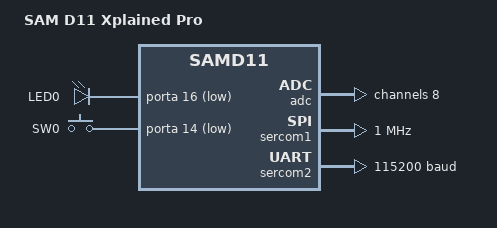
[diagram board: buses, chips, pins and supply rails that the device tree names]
/*
 * Copyright (c) 2018 Sean Nyekjaer
 *
 * SPDX-License-Identifier: Apache-2.0
 */

 /dts-v1/;
 #include <freq.h>
 #include <atmel/samd1x.dtsi>
 #include <atmel/samd11.dtsi>
 //#include <atmel/samx2xx18.dtsi>
 #include "samd11_xpro-pinctrl.dtsi"
 #include <zephyr/dt-bindings/input/input-event-codes.h>
 
 / {
	 model = "SAM D11 Xplained Pro";
	 compatible = "samd11,xpro", "atmel,samd11d14am", "atmel,samd11";
 
	 chosen {
		 zephyr,console = &sercom2;
		 zephyr,shell-uart = &sercom2;
		 zephyr,sram = &sram0;
		 zephyr,flash = &flash0;
	 };
 
	 /* These aliases are provided for compatibility with samples */
	 aliases {
		 led0 = &led0;
		 sw0 = &user_button;
		 serial0 = &sercom0;
         serial1 = &sercom2;
		 adc0 = &adc;
		 //i2c-0 = &sercom2;
	 };
 
	 leds {
		compatible = "gpio-leds";
		led0: led_0 {
			gpios = <&porta 16 GPIO_ACTIVE_LOW>;
			label = "LED0";
		};
	};
 
	 buttons {
		 compatible = "gpio-keys";
		 user_button: button_0 {
			 gpios = <&porta 14 (GPIO_PULL_UP | GPIO_ACTIVE_LOW)>;
			 label = "SW0";
			 zephyr,code = <INPUT_KEY_0>;
		 };
	 };
 };
 
 &cpu0 {
	 clock-frequency = <DT_FREQ_M(48)>;
	 status = "okay";
 };
 

 &adc {
	#address-cells = <1>;
	#size-cells = <0>;
    status = "okay";
	channel@8 {
		reg = <8>;
		zephyr,gain = "ADC_GAIN_1";
		zephyr,reference = "ADC_REF_INTERNAL";
		zephyr,acquisition-time = <ADC_ACQ_TIME_DEFAULT>;
		zephyr,resolution = <10>;
		zephyr,input-positive = <10>;
	};
};


 &sercom1 {
	 status = "okay";
	 compatible = "atmel,sam0-spi";
	 clock-frequency = <1000000>;
	 dipo = <2>;
	 dopo = <3>;
	 #address-cells = <1>;
	 #size-cells = <0>;
	 cs-gpios = <&porta 5 GPIO_ACTIVE_LOW>;
 
	 pinctrl-0 = <&sercom1_spi_default>;
	 pinctrl-names = "default";

 };
 
 &sercom2 {
	status = "okay";
	compatible = "atmel,sam0-uart";
	current-speed = <115200>;
	rxpo = <3>;  //pin 25
	txpo = <2>;  //pin 24


	pinctrl-0 = <&sercom2_uart_default>;
	pinctrl-names = "default";
 };
 
 &sercom0 {
	 status = "disabled";
	 compatible = "atmel,sam0-uart";
	 current-speed = <115200>;
	 rxpo = <3>;  //pin 11
	 txpo = <1>;  //pin 10
 

	 pinctrl-0 = <&sercom0_uart_default>;
	 pinctrl-names = "default";
	
 };
 
 
 &flash0 {
	 partitions {
		 compatible = "fixed-partitions";
		 #address-cells = <1>;
		 #size-cells = <1>;
 
		 /*
		  * The final 16 KiB is reserved for the application.
		  * Storage partition will be used by FCB/LittleFS/NVS
		  * if enabled.
		  */
		 storage_partition: partition@3c000 {
			 label = "storage";
			 reg = <0x0003c000 0x00004000>;
		 };
	 };
 };
 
